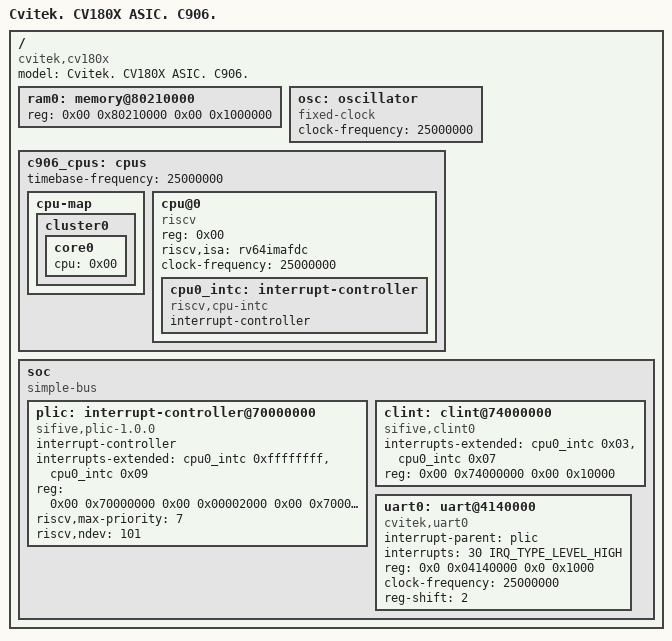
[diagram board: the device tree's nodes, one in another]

#include <zephyr/dt-bindings/interrupt-controller/ite-intc.h>
#include <zephyr/dt-bindings/gpio/gpio.h>

/ {
	#size-cells = <0x2>;
	#address-cells = <0x2>;
	compatible = "cvitek,cv180x";
	model = "Cvitek. CV180X ASIC. C906.";

	ram0: memory@80210000 {
		device_type = "memory";
		reg = <0x00 0x80210000 0x00 0x1000000>;
	};

	osc: oscillator {
		#clock-cells = <0>;
		compatible = "fixed-clock";
		clock-frequency = <25000000>;
	};
#if 0
	clk: clock-controller {
		compatible = "cvitek,cv180x-clk";
		reg = <0x0 0x03002000 0x0 0x1000>;
		clocks = <&osc>;
		#clock-cells = <1>;
	};
#endif
	c906_cpus:cpus {
		#address-cells = <0x01>;
		#size-cells = <0x00>;
		timebase-frequency = <25000000>;

		cpu-map {
			cluster0 {

				core0 {
					cpu = <0x00>;
				};
			};
		};

		cpu@0 {
			device_type = "cpu";
			reg = <0x00>;
			status = "okay";
			compatible = "riscv";
			riscv,isa = "rv64imafdc";
			clock-frequency = <25000000>;

			cpu0_intc: interrupt-controller {
				compatible = "riscv,cpu-intc";
				#address-cells = <0>;
				#interrupt-cells = <1>;
				interrupt-controller;
			};
		};
	};


	soc {
		#address-cells = <0x02>;
		#size-cells = <0x02>;
		compatible = "simple-bus";
		ranges;

		plic: interrupt-controller@70000000 {
			compatible = "sifive,plic-1.0.0";
			#address-cells = <0>;
			#interrupt-cells = <2>;
			interrupt-controller;
			interrupts-extended = <&cpu0_intc 0xffffffff &cpu0_intc 0x09>;
			reg = <0x00 0x70000000 0x00 0x00002000
			       0x00 0x70002000 0x00 0x001fe000
			       0x00 0x70200000 0x00 0x03e00000>;
			reg-names = "prio", "irq_en", "reg";
			riscv,max-priority = <7>;
			riscv,ndev = <101>;
		};

		clint: clint@74000000 {
			compatible = "sifive,clint0";
			interrupts-extended = <&cpu0_intc 0x03 &cpu0_intc 0x07>;
			reg = <0x00 0x74000000 0x00 0x10000>;
		};

		uart0: uart@4140000 {
			compatible = "cvitek,uart0";
			interrupt-parent = <&plic>;
			interrupts = <30 IRQ_TYPE_LEVEL_HIGH>;
			reg = <0x0 0x04140000 0x0 0x1000>;
			reg-names = "control";
			clock-frequency = <25000000>;
			reg-shift = <2>;
			status = "okay";
		};
	};


};
